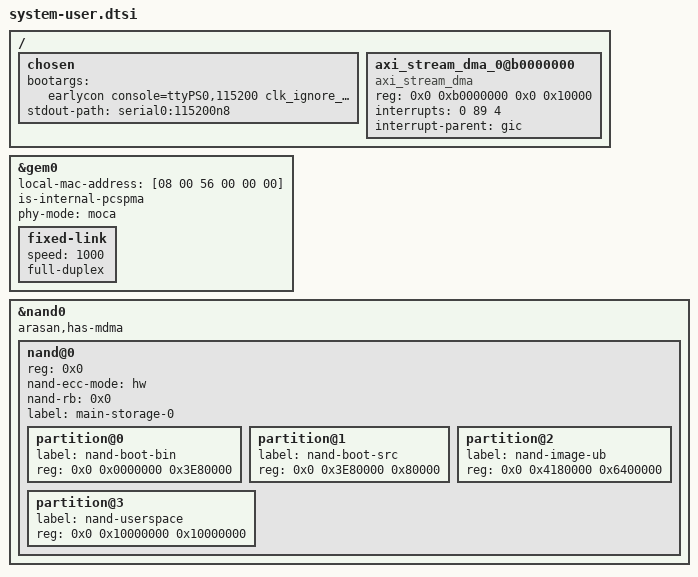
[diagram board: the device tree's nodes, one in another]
/ {
	chosen {
		bootargs = " earlycon console=ttyPS0,115200 clk_ignore_unused root=/dev/ram0 rw";
		stdout-path = "serial0:115200n8";
	};
};
&gem0 {
	local-mac-address = [08 00 56 00 00 00];
	is-internal-pcspma;
	phy-mode = "moca";
	fixed-link {
		speed = <1000>;
		full-duplex;
	};
};
/ {
	axi_stream_dma_0@b0000000 {
		compatible = "axi_stream_dma";
		reg = <0x0 0xb0000000 0x0 0x10000>;
		interrupts = <0 89 4>;
		interrupt-parent = <&gic>;
	};
};
&nand0 {
	status = "okay";
	arasan,has-mdma;

	nand@0 {
		reg = <0x0>;
		#address-cells = <0x2>;
		#size-cells = <0x1>;
		nand-ecc-mode = "hw";
		nand-rb = <0x0>;
		label = "main-storage-0";
		partition@0 {
			label = "nand-boot-bin";
			reg = <0x0 0x0000000 0x3E80000>;
		};
		partition@1 {
			label = "nand-boot-src";
			reg = <0x0 0x3E80000 0x80000>;
		};
		partition@2 {
			label = "nand-image-ub";
			reg = <0x0 0x4180000 0x6400000>;
		};
		partition@3 {
			label = "nand-userspace";
			reg = <0x0 0x10000000 0x10000000>;
		};
	};
};
